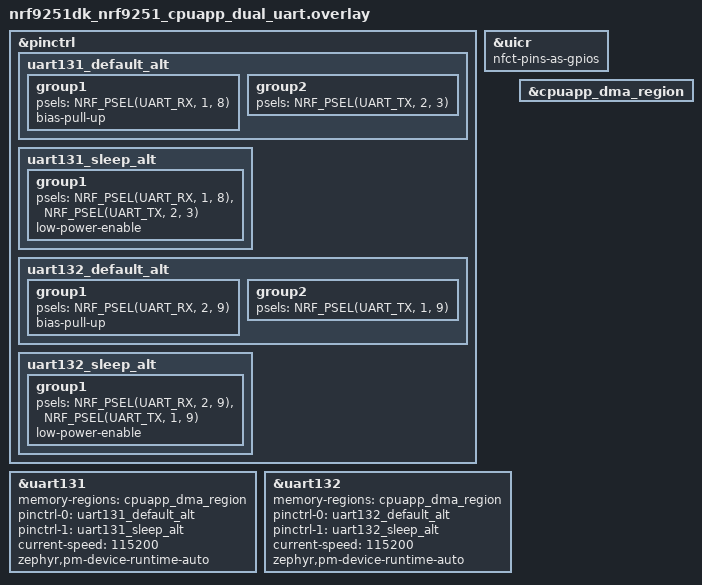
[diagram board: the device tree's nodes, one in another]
/*
 * Copyright (c) 2026 Nordic Semiconductor ASA
 *
 * SPDX-License-Identifier: LicenseRef-Nordic-5-Clause
 */

/* Test requires loopbacks:
 * TX1-RX1: P2.03 - P2.09
 * TX2-RX2: P1.08 - P1.09 (connected with NFCT antena)
 */

&pinctrl {
	uart131_default_alt: uart131_default_alt {
		group1 {
			psels = <NRF_PSEL(UART_RX, 1, 8)>;
			bias-pull-up;
		};

		group2 {
			psels = <NRF_PSEL(UART_TX, 2, 3)>;
		};
	};

	uart131_sleep_alt: uart131_sleep_alt {
		group1 {
			psels = <NRF_PSEL(UART_RX, 1, 8)>,
				<NRF_PSEL(UART_TX, 2, 3)>;
			low-power-enable;
		};
	};

	uart132_default_alt: uart132_default_alt {
		group1 {
			psels = <NRF_PSEL(UART_RX, 2, 9)>;
			bias-pull-up;
		};

		group2 {
			psels = <NRF_PSEL(UART_TX, 1, 9)>;
		};
	};

	uart132_sleep_alt: uart132_sleep_alt {
		group1 {
			psels = <NRF_PSEL(UART_RX, 2, 9)>,
				<NRF_PSEL(UART_TX, 1, 9)>;
			low-power-enable;
		};
	};
};

&uicr {
	nfct-pins-as-gpios;
};

dut: &uart131 {
	status = "okay";
	memory-regions = <&cpuapp_dma_region>;
	pinctrl-0 = <&uart131_default_alt>;
	pinctrl-1 = <&uart131_sleep_alt>;
	pinctrl-names = "default", "sleep";
	current-speed = <115200>;
	zephyr,pm-device-runtime-auto;
};

dut_aux: &uart132 {
	status = "okay";
	memory-regions = <&cpuapp_dma_region>;
	pinctrl-0 = <&uart132_default_alt>;
	pinctrl-1 = <&uart132_sleep_alt>;
	pinctrl-names = "default", "sleep";
	current-speed = <115200>;
	zephyr,pm-device-runtime-auto;
};

&cpuapp_dma_region {
	status = "okay";
};
